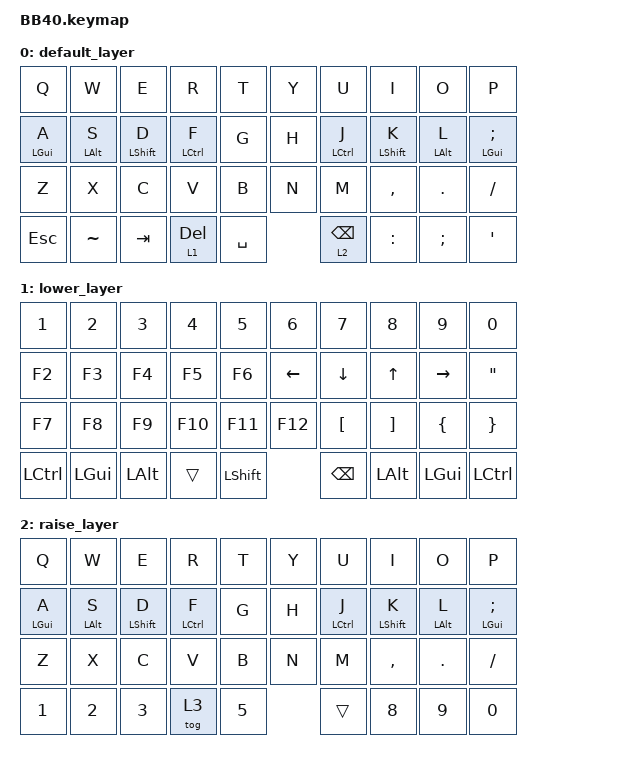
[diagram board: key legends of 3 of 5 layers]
/*
 * Copyright (c) 2022 The ZMK Contributors
 *
 * SPDX-License-Identifier: MIT
 */

#include <behaviors.dtsi>
#include <dt-bindings/zmk/keys.h>
#include <dt-bindings/zmk/bt.h>
#include <dt-bindings/zmk/outputs.h>

&encoder_1 {
    status = "okay";
};

#define DEFAULT 0
#define LOWER   1
#define RAISE   2
#define CONTROL 3
#define NAV     4

/ {
    behaviors {
        td_lx: tap_dance_layers {
            compatible = "zmk,behavior-tap-dance";
            label = "TAP_DANCE_LAYERS";
            #binding-cells = <0>;
            tapping-term-ms = <170>;
            bindings = <&mo 1>, <&mo 2>, <&mo 3>;
        };
        td_rx: tap_dance_layers_r {
            compatible = "zmk,behavior-tap-dance";
            label = "TAP_DANCE_LAYERS_RIGHT";
            #binding-cells = <0>;
            tapping-term-ms = <170>;
            bindings = <&mo 4>, <&mo 2>, <&mo 3>;
        };
    };
    sensors {
        compatible = "zmk,keymap-sensors";
        sensors = <&encoder_1>;
        triggers-per-rotation = <20>;
    };

	keymap {
		compatible = "zmk,keymap";

		default_layer {
			bindings = <
        &kp Q            &kp W            &kp E              &kp R         &kp T      &kp Y  &kp U            &kp I              &kp O            &kp P
        &hml LEFT_GUI A  &hml LEFT_ALT S  &hml LEFT_SHIFT D  &hml LCTRL F  &kp G      &kp H  &hmr LCTRL J     &hmr LEFT_SHIFT K  &hmr LEFT_ALT L  &hmr LEFT_GUI SEMI
        &kp Z            &kp X            &kp C              &kp V         &kp B      &kp N  &kp M            &kp COMMA          &kp DOT          &kp SLASH
        &kp ESCAPE       &kp TILDE        &kp TAB            &lt 1 DEL     &kp SPACE         &lt 2 BACKSPACE  &kp COLON          &kp SEMI         &kp SINGLE_QUOTE
			>;
            sensor-bindings = <&inc_dec_kp RIGHT LEFT>;
		};

		lower_layer {
			bindings = <
        &kp NUMBER_1  &kp NUMBER_2  &kp NUMBER_3  &kp NUMBER_4  &kp NUMBER_5    &kp NUMBER_6  &kp N7            &kp N8             &kp N9          &kp N0
        &kp F2        &kp F3        &kp F4        &kp F5        &kp F6          &kp LEFT      &kp DOWN_ARROW    &kp UP_ARROW       &kp RIGHT       &kp DOUBLE_QUOTES
        &kp F7        &kp F8        &kp F9        &kp F10       &kp F11         &kp F12       &kp LEFT_BRACKET  &kp RIGHT_BRACKET  &kp LEFT_BRACE  &kp RIGHT_BRACE
        &kp LCTRL     &kp LEFT_GUI  &kp LEFT_ALT  &trans        &kp LEFT_SHIFT                &kp BACKSPACE     &kp LEFT_ALT       &kp LEFT_GUI    &kp LCTRL
			>;
            sensor-bindings = <&inc_dec_kp DOWN UP>;

		};

        raise_layer {
			bindings = <
        &kp Q            &kp W            &kp E              &kp R         &kp T   &kp Y  &kp U         &kp I              &kp O            &kp P
        &hml LEFT_GUI A  &hml LEFT_ALT S  &hml LEFT_SHIFT D  &hml LCTRL F  &kp G   &kp H  &hmr LCTRL J  &hmr LEFT_SHIFT K  &hmr LEFT_ALT L  &hmr LEFT_GUI SEMI
        &kp Z            &kp X            &kp C              &kp V         &kp B   &kp N  &kp M         &kp COMMA          &kp DOT          &kp SLASH
        &kp N1           &kp N2           &kp N3             &tog 3        &kp N5         &trans        &kp N8             &kp N9           &kp N0
			>;
            sensor-bindings = <&inc_dec_kp PG_DN PG_UP>;
		};

        control_layer {
			bindings = <
                &trans     &bt BT_SEL 0 &bt BT_SEL 1 &bt BT_SEL 2 &bt BT_SEL 3 &bt BT_SEL 4 &trans &trans &trans &trans    &trans        &trans
                &trans     &kp A      &kp S      &kp D     &kp F     &kp G      &kp H     &kp J     &kp K       &kp PSCRN                &kp CAPS
                &trans     &bt BT_NXT &bt BT_PRV &kp C     &kp V     &bt BT_CLR &kp N     &kp M     &kp KP_NLCK            &kp SLCK      &kp INS
                &trans     &trans    &trans    &trans              &trans               &trans                &trans       &trans        &trans       &trans
			>;
            sensor-bindings = <&inc_dec_kp C_VOL_DN C_VOL_UP>;
		};

        nav_layer {
			bindings = <
                &kp TAB    &kp Q     &kp W     &kp F     &kp P     &kp B      &kp J     &kp L     &kp U       &kp Y        &kp ENTER     &kp BSPC
                &kp LCTRL  &kp A     &kp R     &kp S     &kp T     &kp G      &kp PG_UP &kp HOME  &kp UP      &kp END                    &kp O
                &kp LSHFT  &kp Z     &kp X     &kp C     &kp D     &kp V      &kp PG_DN &kp LEFT  &kp DOWN                &kp RIGHT     &kp RSHFT
                &trans     &trans    &trans    &trans              &trans               &trans                &trans       &trans        &trans       &trans
			>;
            sensor-bindings = <&inc_dec_kp C_VOL_DN C_VOL_UP>;
		};
	};
};
